# haltium_secure register map
Vendor: Nordic Semiconductor; Series: nRFHaltium; File version: 1
CPU: CM33 r0p4, little endian, MPU, FPU, 3 interrupt priority bits, 480 interrupts
Registers are 32-bit, read-write, reset 0x0 unless marked. A register's access mark holds for its fields unless they carry their own. Offsets are from the block's base; [hi:lo] are bit positions; lines under a group give offsets from that group; {n}, {i} and the like mark numbered series; 'fields as' and 'values as' point back to an identical list.

## MUTEX_NS — MUTEX 0
Base 0x41017000
Same registers: GLOBAL_GMUTEX0_NS 0x4F8D2000, GLOBAL_GMUTEX1_NS 0x4F927000, MUTEX_S 0x51017000
{0x400+4i} MUTEX[{i}] (i=0..15) — Description collection: Mutex register
  [0] MUTEX — Mutex register n
    0=Unlocked (Mutex n is in unlocked state); 1=Locked (Mutex n is in locked state)

## BELLBOARD_NS — BELLBOARD APB registers 0
Base 0x4F099000
Same registers: BELLBOARD_S 0x5F099000
{0x0+4i} TASKS_SIGNAL[{i}] (i=0..31) wo — Description collection: Signal [n] task
  [0] TASKS_SIGNAL — Signal [n] task
    1=Trigger task
{0x100+4i} EVENTS_SIGNALSET[{i}] (i=0..31) — Description collection: Signal set [n] event
  [0] EVENTS_SIGNALSET — Signal set [n] event
    0=NotGenerated (Event not generated); 1=Generated (Event generated)
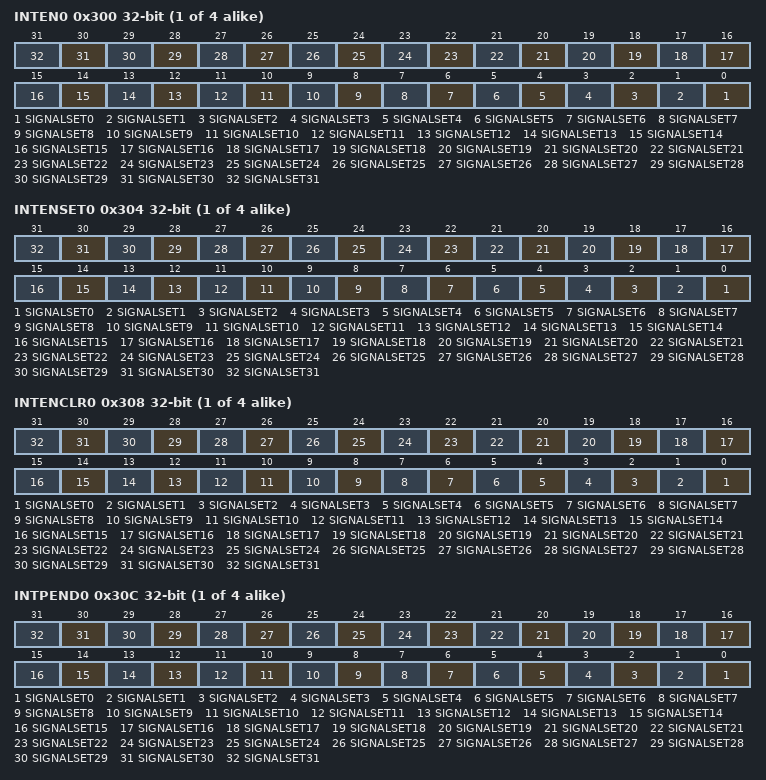
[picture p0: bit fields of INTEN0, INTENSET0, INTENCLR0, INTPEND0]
{0x300+0x10*i} INTEN{i} (i=0..3) — Enable or disable interrupt
  [all] fields
    0=Disabled; 1=Enabled
  [n] SIGNALSET{n} (n=0..31) — Enable or disable interrupt for event SIGNALSET[{n}]
{0x304+0x10*i} INTENSET{i} (i=0..3) — Enable interrupt
  [all] fields
    on read: 0=Disabled (Read: Disabled); 1=Enabled (Read: Enabled) | on write: 1=Set (Enable)
  [n] SIGNALSET{n} (n=0..31) — Write '1' to enable interrupt for event SIGNALSET[{n}]
{0x308+0x10*i} INTENCLR{i} (i=0..3) — Disable interrupt
  [all] fields
    on read: 0=Disabled (Read: Disabled); 1=Enabled (Read: Enabled) | on write: 1=Clear (Disable)
  [n] SIGNALSET{n} (n=0..31) — Write '1' to disable interrupt for event SIGNALSET[{n}]
{0x30C+0x10*i} INTPEND{i} ro (i=0..3) — Pending interrupts
  [all] fields
    on read: 0=NotPending (Read: Not pending); 1=Pending (Read: Pending)
  [n] SIGNALSET{n} (n=0..31) — Read pending status of interrupt for event SIGNALSET[{n}]

## GLOBAL_GIPCT0_NS — IPCT APB registers 0
Base 0x4F8D1000
Same registers: GLOBAL_GIPCT1_NS 0x4F921000, GLOBAL_GIPCT0_S 0x5F8D1000, GLOBAL_GIPCT1_S 0x5F921000
{0x0+4i} TASKS_SEND[{i}] (i=0..15) wo — Description collection: Send [n] task
  [0] TASKS_SEND — Send [n] task
    1=Trigger task
{0x40+4i} TASKS_ACK[{i}] (i=0..15) wo — Description collection: Acknowledge the RECEIVE[n] event
  [0] TASKS_ACK — Acknowledge the RECEIVE[n] event
    1=Trigger task
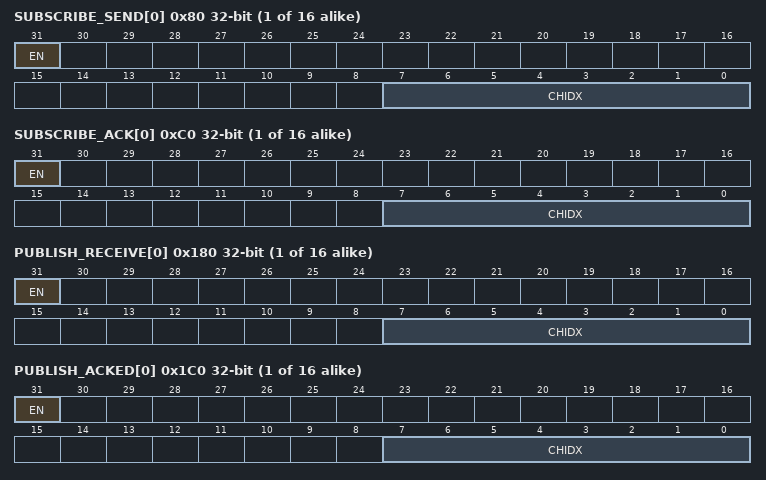
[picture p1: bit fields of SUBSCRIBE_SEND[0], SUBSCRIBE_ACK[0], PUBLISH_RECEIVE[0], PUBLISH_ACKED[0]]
{0x80+4i} SUBSCRIBE_SEND[{i}] (i=0..15) — Description collection: Subscribe configuration for task SEND[n]
  [31] EN
    0=Disabled (Disable subscription); 1=Enabled (Enable subscription)
  [7:0] CHIDX — DPPI channel that task SEND[n] will subscribe to
{0xC0+4i} SUBSCRIBE_ACK[{i}] (i=0..15) — Description collection: Subscribe configuration for task ACK[n]
  [31] EN
    values as SUBSCRIBE_SEND[0].EN
  [7:0] CHIDX — DPPI channel that task ACK[n] will subscribe to
{0x100+4i} EVENTS_RECEIVE[{i}] (i=0..15) — Description collection: Receive [n] event
  [0] EVENTS_RECEIVE — Receive [n] event
    0=NotGenerated (Event not generated); 1=Generated (Event generated)
{0x140+4i} EVENTS_ACKED[{i}] (i=0..15) — Description collection: Acknowledged event for the SEND[n] task
  [0] EVENTS_ACKED — Acknowledged event for the SEND[n] task
    values as EVENTS_RECEIVE[0].EVENTS_RECEIVE
{0x180+4i} PUBLISH_RECEIVE[{i}] (i=0..15) — Description collection: Publish configuration for event RECEIVE[n]
  [31] EN
    0=Disabled (Disable publishing); 1=Enabled (Enable publishing)
  [7:0] CHIDX — DPPI channel that event RECEIVE[n] will publish to
{0x1C0+4i} PUBLISH_ACKED[{i}] (i=0..15) — Description collection: Publish configuration for event ACKED[n]
  [31] EN
    values as PUBLISH_RECEIVE[0].EN
  [7:0] CHIDX — DPPI channel that event ACKED[n] will publish to
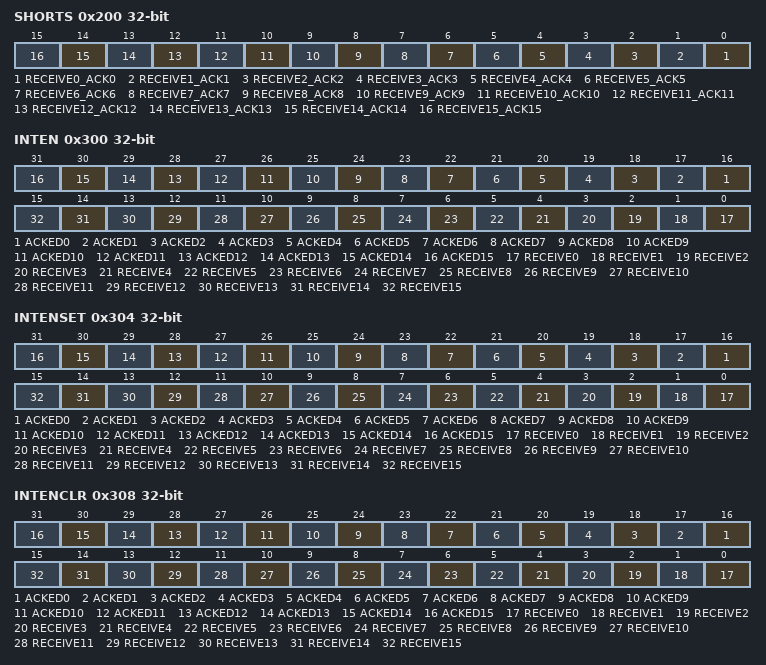
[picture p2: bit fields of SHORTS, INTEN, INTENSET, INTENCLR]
0x200 SHORTS — Shortcuts between local events and tasks
  [all] fields
    0=Disabled (Disable shortcut); 1=Enabled (Enable shortcut)
  [n] RECEIVE{n}_ACK{n} (n=0..15) — Shortcut between event RECEIVE[{n}] and task ACK[{n}]
0x300 INTEN — Enable or disable interrupt
  [all] fields
    0=Disabled; 1=Enabled
  [n+16] ACKED{n} (n=0..15) — Enable or disable interrupt for event ACKED[{n}]
  [n] RECEIVE{n} (n=0..15) — Enable or disable interrupt for event RECEIVE[{n}]
0x304 INTENSET — Enable interrupt
  [all] fields
    on read: 0=Disabled (Read: Disabled); 1=Enabled (Read: Enabled) | on write: 1=Set (Enable)
  [n+16] ACKED{n} (n=0..15) — Write '1' to enable interrupt for event ACKED[{n}]
  [n] RECEIVE{n} (n=0..15) — Write '1' to enable interrupt for event RECEIVE[{n}]
0x308 INTENCLR — Disable interrupt
  [all] fields
    on read: 0=Disabled (Read: Disabled); 1=Enabled (Read: Enabled) | on write: 1=Clear (Disable)
  [n+16] ACKED{n} (n=0..15) — Write '1' to disable interrupt for event ACKED[{n}]
  [n] RECEIVE{n} (n=0..15) — Write '1' to disable interrupt for event RECEIVE[{n}]
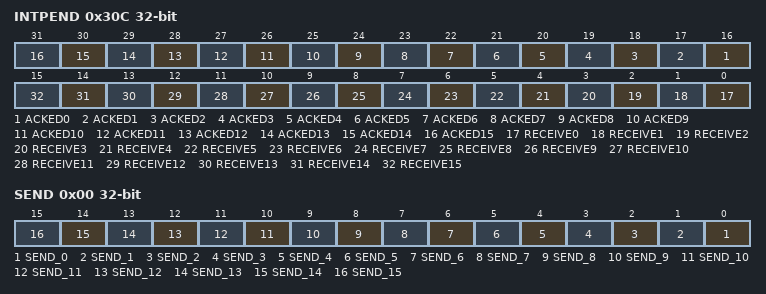
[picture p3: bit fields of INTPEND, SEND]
0x30C INTPEND ro — Pending interrupts
  [all] fields
    on read: 0=NotPending (Read: Not pending); 1=Pending (Read: Pending)
  [n+16] ACKED{n} (n=0..15) — Read pending status of interrupt for event ACKED[{n}]
  [n] RECEIVE{n} (n=0..15) — Read pending status of interrupt for event RECEIVE[{n}]
0x400 OVERFLOW group — Unspecified
  0x00 SEND — The task overflow status for SEND tasks Write 0 to clear
    [all] fields
      1=Overflow (Task overflow is happened); 0=NoOverflow (Task overflow is not happened)
    [n] SEND_{n} (n=0..15) — The status for SEND [{n}] task overflow
